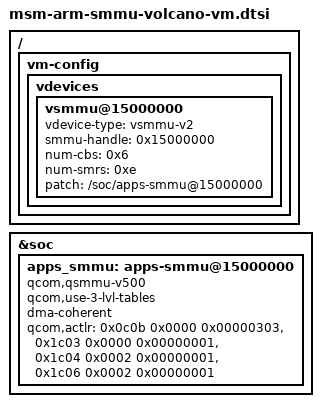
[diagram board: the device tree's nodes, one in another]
#include <dt-bindings/interrupt-controller/arm-gic.h>

/ {
	vm-config {
		vdevices {
			vsmmu@15000000 {
				vdevice-type = "vsmmu-v2";
				smmu-handle = <0x15000000>;
				num-cbs = <0x6>;
				num-smrs = <0xe>;
				patch = "/soc/apps-smmu@15000000";
			};
		};
	};
};

&soc {
	apps_smmu: apps-smmu@15000000 {
		/*
		 * reg, #global-interrupts & interrupts  properties will
		 * be added dynamically by bootloader.
		 */
		compatible = "qcom,qsmmu-v500", "qcom,virt-smmu";
		#iommu-cells = <2>;
		qcom,use-3-lvl-tables;
		dma-coherent;

		qcom,actlr =
			/* Compute */
			<0x0c0b 0x0000 0x00000303>,

			/* Display */
			<0x1c03 0x0000 0x00000001>,
			<0x1c04 0x0002 0x00000001>,
			<0x1c06 0x0002 0x00000001>;
	};
};
